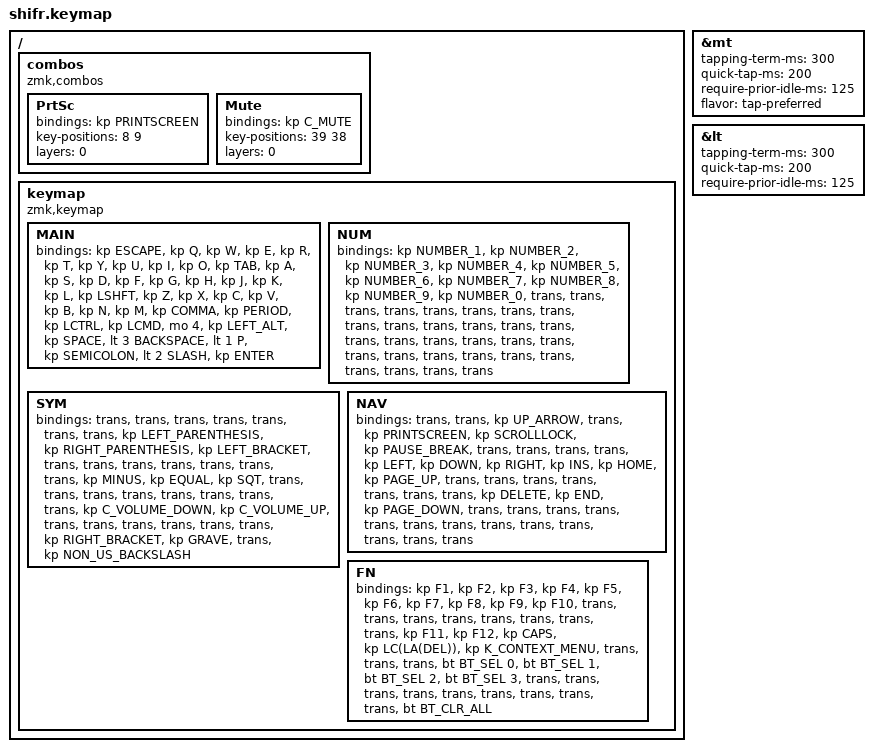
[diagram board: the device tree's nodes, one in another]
#include <behaviors.dtsi>
#include <dt-bindings/zmk/bt.h>
#include <dt-bindings/zmk/keys.h>

&mt {
    tapping-term-ms = <300>;
    quick-tap-ms = <200>;
    require-prior-idle-ms = <125>;
    flavor = "tap-preferred";
};

&lt {
    tapping-term-ms = <300>;
    quick-tap-ms = <200>;
    require-prior-idle-ms = <125>;
};

/ {
    combos {
        compatible = "zmk,combos";

        PrtSc {
            bindings = <&kp PRINTSCREEN>;
            key-positions = <8 9>;
            layers = <0>;
        };

        Mute {
            bindings = <&kp C_MUTE>;
            key-positions = <39 38>;
            layers = <0>;
        };
    };

    keymap {
        compatible = "zmk,keymap";

        MAIN {
            bindings = <
&kp ESCAPE  &kp Q  &kp W  &kp E  &kp R  &kp T  &kp Y  &kp U  &kp I  &kp O  &kp TAB  &kp A  &kp S  &kp D  &kp F  &kp G  &kp H  &kp J  &kp K  &kp L  &kp LSHFT  &kp Z  &kp X  &kp C  &kp V  &kp B  &kp N  &kp M  &kp COMMA  &kp PERIOD  &kp LCTRL  &kp LCMD  &mo 4  &kp LEFT_ALT  &kp SPACE  &lt 3 BACKSPACE  &lt 1 P  &kp SEMICOLON  &lt 2 SLASH  &kp ENTER
            >;
        };

        NUM {
            bindings = <
&kp NUMBER_1  &kp NUMBER_2  &kp NUMBER_3  &kp NUMBER_4  &kp NUMBER_5  &kp NUMBER_6  &kp NUMBER_7  &kp NUMBER_8  &kp NUMBER_9  &kp NUMBER_0  &trans  &trans  &trans  &trans  &trans  &trans  &trans  &trans  &trans  &trans  &trans  &trans  &trans  &trans  &trans  &trans  &trans  &trans  &trans  &trans  &trans  &trans  &trans  &trans  &trans  &trans  &trans  &trans  &trans  &trans
            >;
        };

        SYM {
            bindings = <
&trans  &trans  &trans  &trans  &trans  &trans  &trans  &kp LEFT_PARENTHESIS  &kp RIGHT_PARENTHESIS  &kp LEFT_BRACKET  &trans  &trans  &trans  &trans  &trans  &trans  &trans  &kp MINUS  &kp EQUAL  &kp SQT  &trans  &trans  &trans  &trans  &trans  &trans  &trans  &trans  &kp C_VOLUME_DOWN  &kp C_VOLUME_UP  &trans  &trans  &trans  &trans  &trans  &trans  &kp RIGHT_BRACKET  &kp GRAVE  &trans  &kp NON_US_BACKSLASH
            >;
        };

        NAV {
            bindings = <
&trans  &trans  &kp UP_ARROW  &trans  &kp PRINTSCREEN  &kp SCROLLLOCK  &kp PAUSE_BREAK  &trans  &trans  &trans  &trans  &kp LEFT  &kp DOWN  &kp RIGHT  &kp INS  &kp HOME  &kp PAGE_UP  &trans  &trans  &trans  &trans  &trans  &trans  &trans  &kp DELETE  &kp END  &kp PAGE_DOWN  &trans  &trans  &trans  &trans  &trans  &trans  &trans  &trans  &trans  &trans  &trans  &trans  &trans
            >;
        };

        FN {
            bindings = <
&kp F1  &kp F2  &kp F3  &kp F4  &kp F5  &kp F6  &kp F7  &kp F8  &kp F9  &kp F10  &trans  &trans  &trans  &trans  &trans  &trans  &trans  &trans  &kp F11  &kp F12  &kp CAPS  &kp LC(LA(DEL))  &kp K_CONTEXT_MENU  &trans  &trans  &trans  &bt BT_SEL 0  &bt BT_SEL 1  &bt BT_SEL 2  &bt BT_SEL 3  &trans  &trans  &trans  &trans  &trans  &trans  &trans  &trans  &trans  &bt BT_CLR_ALL
            >;
        };
    };
};
